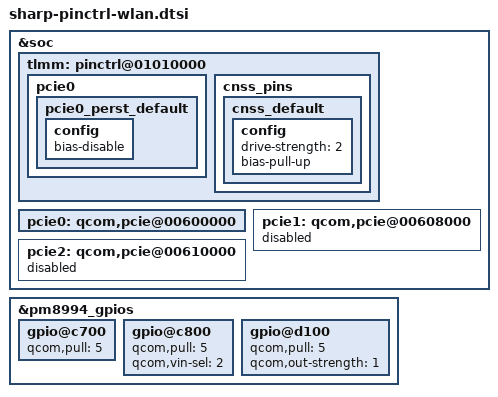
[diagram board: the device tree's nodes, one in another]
/* Copyright (c) 2015, The Linux Foundation. All rights reserved.
 *
 * This program is free software; you can redistribute it and/or modify
 * it under the terms of the GNU General Public License version 2 and
 * only version 2 as published by the Free Software Foundation.
 *
 * This program is distributed in the hope that it will be useful,
 * but WITHOUT ANY WARRANTY; without even the implied warranty of
 * MERCHANTABILITY or FITNESS FOR A PARTICULAR PURPOSE.  See the
 * GNU General Public License for more details.
 */

&soc {
	tlmm: pinctrl@01010000 {
		pcie0 {
			/* GPIO35*/
			pcie0_perst_default: pcie0_perst_default {
				config {
					/delete-property/ bias-pull-down;
					bias-disable;
				};
			};
		};
/* [WLAN][SHARP] 2016.01.29 Mod for GPIO 46 Start */
		cnss_pins {
			cnss_default: cnss_default {
				config {
					drive-strength = <2>;
					/delete-property/ bias-pull-down;
					bias-pull-up;
				};
			};
		};
/* [WLAN][SHARP] 2016.01.29 Mod for GPIO 46 End */
	};

	pcie0: qcom,pcie@00600000 {
		status = "ok";
	};

	pcie1: qcom,pcie@00608000 {
		status = "disabled";
	};

	pcie2: qcom,pcie@00610000 {
		status = "disabled";
	};
};

&pm8994_gpios {
	gpio@c700 { /* GPIO 8 - WLAN_EN */
		qcom,pull = <5>;		/* QPNP_PIN_PULL_NO */
	};

	gpio@c800 { /* GPIO 9 - Rome 3.3V control */
		qcom,pull = <5>;		/* QPNP_PIN_PULL_NO */
		qcom,vin-sel = <2>;		/* QPNP_PIN_VIN2 */
	};

	gpio@d100 { /* GPIO 18 - Rome Sleep Clock */
		qcom,pull = <5>;		/* QPNP_PIN_PULL_NO */
		qcom,out-strength = <1>;	/* Low */
	};
};
